# haltium_secure register map
Vendor: Nordic Semiconductor; Series: nRFHaltium; File version: 1
CPU: CM33 r0p4, little endian, MPU, FPU, 3 interrupt priority bits, 480 interrupts
Registers are 32-bit, read-write, reset 0x0 unless marked. A register's access mark holds for its fields unless they carry their own. Offsets are from the block's base; [hi:lo] are bit positions; lines under a group give offsets from that group; {n}, {i} and the like mark numbered series; 'fields as' and 'values as' point back to an identical list.

## ICACHEDATA_S — CACHEDATA 0
Base 0x01F00000
Same registers: DCACHEDATA_S 0x21F00000
{0x0+0x40*i} SET[{i}] (i=0..255) group — Unspecified
  {0x0+0x20*j} WAY[{j}] (j=0..1) group — Unspecified
    {0x0+8k} DU[{k}] (k=0..3) group — Unspecified
      {0x0+4l} DATA[{l}] (l=0..1) — Description collection: Cache data bits for DATA[q] in DU[p] (DataUnit) of SET[n], WAY[o].
        [31:0] Data

## ICACHEINFO_S — CACHEINFO 0
Base 0x01F10000
Same registers: DCACHEINFO_S 0x21F10000
{0x0+8i} SET[{i}] (i=0..255) group — Unspecified
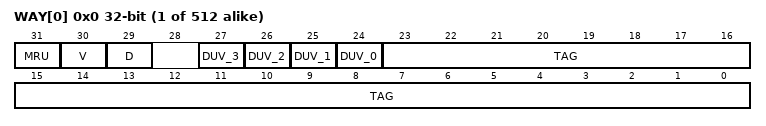
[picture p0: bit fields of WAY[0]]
  {0x0+4j} WAY[{j}] (j=0..1) — Description collection: Cache information for SET[n], WAY[o].
    [31] MRU ro — Most recently used way.
      0=Way0 was most recently used; 1=Way1 was most recently used
    [30] V ro — Line valid bit.
      0=Invalid cache line; 1=Valid cache line
    [29] D ro — Line dirty bit.
      0=Clean cache line; 1=Dirty cache line
    [n+24] DUV_{n} ro (n=0..3) — Data unit valid info.
      0=Invalid data unit; 1=Valid data unit
    [23:0] TAG ro — Cache tag.

## RICR_S — ROM Information Configuration Registers
Base 0x0FFFC000
0x00 LCS group — Unspecified
  {0x0+4j} SIGNATURE[{j}] (j=0..3) reset 0xFFFFFFFF — Description collection: Signature to determine the re-entrant device life-cycle state (LCS).
    [31:0] VALUE — Uninitialized when freshly out of factory, esle PUF-derived LCS signature.
      0xFFFFFFFF=UNINITIALIZED (Value of LCS registers when the device is freshly manufactured (LCS state FFF), and the MRAM and the info pages including RICR are uninitialized.)
0x10 SECFW group — Unspecified
  0x00 TIMESTAMP reset 0xFFFFFFFF — Register used for downgrade prevention of the secure domain firmware.
    [31:0] TIMESTAMP — Timestamp of the current secure down firmware, if the downgrade prevention feature is enabled.

## GLOBAL_STMDATA_NS — System Trace Macrocell data buffer
Base 0xA0000000
{0x0+0x2000000*i} DOMAIN[{i}] (i=0..15) group — Unspecified
  {0x0+j} NSDATA[{j}] (j=0..16777215) 8-bit — Description collection: NonSecure STM output data buffer for domain n. Writes to this region generates trace packets with id n+96.
  {0x1000000+j} SDATA[{j}] (j=0..16777215) 8-bit — Description collection: Secure STM output data buffer for domain n. Writes to this region generates trace packets with id n+32.
{0x0+0x1000000*i} BUFFER[{i}] (i=0..15) group (alternate view of DOMAIN[{i}]) — Raw buffer access to STM array. Use when DOMAIN array does not apply.
  {0x0+j} DATA[{j}] (j=0..16777215) 8-bit — Description collection: STM output data buffer n. Writes to this region generates trace packets.

## GLOBAL_TDDCONF_S — TDDCONF
Base 0xBF001000
0x400 SYSPWRUPREQ — System power-up request
  [0] ACTIVE — Activate power-up request
    0=NotActive (Power-up request not active); 1=Active (Power-up request active)
0x404 DBGPWRUPREQ — Debug power-up request
  fields as SYSPWRUPREQ
0x408 TRACEPORTSPEED — Trace port trace clock speed
  [1:0] SPEED — Trace clock speed
    0=Speed25MHz; 1=Speed12500KHz (Speed 12.5MHz); 2=Speed6250KHz (Speed 6.25MHz); 3=Speed3125KHz (Speed 3.125MHz)
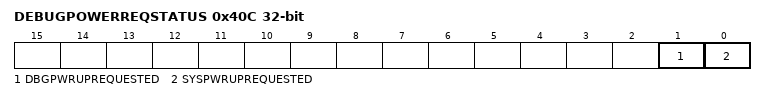
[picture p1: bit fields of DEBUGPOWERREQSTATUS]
0x40C DEBUGPOWERREQSTATUS ro — Combined effective system status of both SWJ-DP and TDDCONF registers originated power requests
  [1] DBGPWRUPREQUESTED — Debug domain powerup request status
    0=NoPowerReq (Power not requested); 1=Power requested
  [0] SYSPWRUPREQUESTED — System powerup request status
    0=NoPowerReq (Power not requested); 1=Power requested

## CTRLAP_S — Control access port
Base 0xBF002000
0x100 EVENTS_RXREADY — The RXSTATUS is changed to DataPending
  [0] EVENTS_RXREADY
    0=NotGenerated (Event not generated); 1=Generated (Event generated)
0x104 EVENTS_TXDONE — The TXSTATUS is changed to NoDataPending
  [0] EVENTS_TXDONE
    values as EVENTS_RXREADY.EVENTS_RXREADY
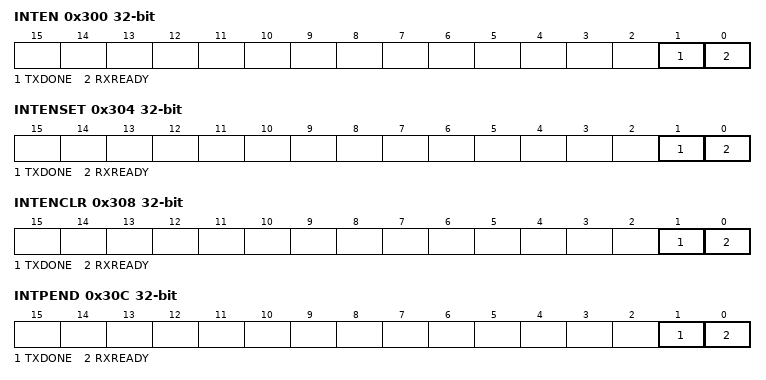
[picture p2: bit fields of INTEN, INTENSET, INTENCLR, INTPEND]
0x300 INTEN — Enable or disable interrupt
  [1] TXDONE — Enable or disable interrupt for event TXDONE
    0=Disabled; 1=Enabled
  [0] RXREADY — Enable or disable interrupt for event RXREADY
    0=Disabled; 1=Enabled
0x304 INTENSET — Enable interrupt
  [1] TXDONE — Write '1' to enable interrupt for event TXDONE
    on read: 0=Disabled (Read: Disabled); 1=Enabled (Read: Enabled) | on write: 1=Set (Enable)
  [0] RXREADY — Write '1' to enable interrupt for event RXREADY
    values as TXDONE
0x308 INTENCLR — Disable interrupt
  [1] TXDONE — Write '1' to disable interrupt for event TXDONE
    on read: 0=Disabled (Read: Disabled); 1=Enabled (Read: Enabled) | on write: 1=Clear (Disable)
  [0] RXREADY — Write '1' to disable interrupt for event RXREADY
    values as TXDONE
0x30C INTPEND ro — Pending interrupts
  [1] TXDONE — Read pending status of interrupt for event TXDONE
    on read: 0=NotPending (Read: Not pending); 1=Pending (Read: Pending)
  [0] RXREADY — Read pending status of interrupt for event RXREADY
    values as TXDONE
0x400 MAILBOX group — Unspecified
  0x00 RXDATA ro — Data sent from the debugger to the CPU
    [31:0] RXDATA — Data received from debugger
  0x04 RXSTATUS ro — Status to indicate if data sent from the debugger to the CPU has been read
    [0] RXSTATUS — Status of data in register RXDATA
      0=No data pending in register RXDATA; 1=Data pending in register RXDATA
  0x80 TXDATA — Data sent from the CPU to the debugger
    [31:0] TXDATA — Data sent to debugger
  0x84 TXSTATUS ro — Status to indicate if data sent from the CPU to the debugger has been read
    [0] TXSTATUS — Status of data in register TXDATA
      0=No data pending in register TXDATA; 1=Data pending in register TXDATA
  0x88 BOOTMODE ro — Secure domain boot mode.
    [0] MODE
      0=Normal mode of operation; 1=ROM operation mode
0x500 INFO group — Unspecified
  0x00 PARTNO — Part number of the device
    [31:0] PARTNO — Part number
  0x04 HWREVISION — Hardware Revision of the device
    [31:0] ID — Part Variant
  0x08 READY reset 0x1 — The INFO registers ready status.
    [0] READY — Ready status.
      0=Ready; 1=NotReady (Not reday)
